# STM32L562 register map
File version: 1.1
Registers are 16-bit, read-write, reset 0x0 unless marked. A register's access mark holds for its fields unless they carry their own. Offsets are from the block's base; lines under a group give offsets from that group; [hi:lo] are bit positions; {n}, {i} and the like mark numbered series; 'fields as' and 'values as' point back to an identical list; <NAME> marks a mode.

## Memory map
0x4000D400 USB size 0x800 — Universal serial bus full-speed device interface

## Interrupts
73 USB_FS (USB) — USB FS global interrupt

## USB — Universal serial bus full-speed device interface
Base 0x4000D400
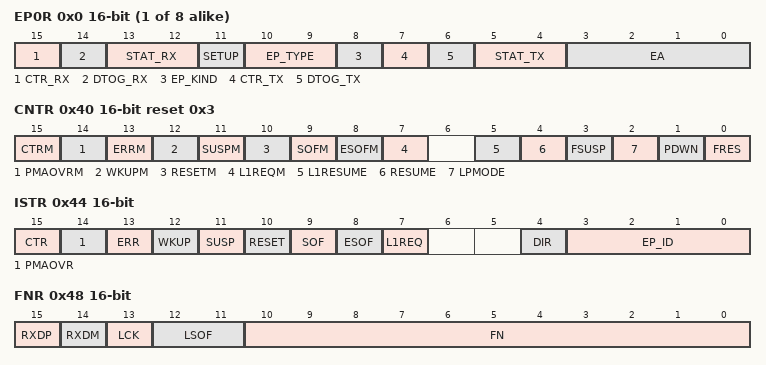
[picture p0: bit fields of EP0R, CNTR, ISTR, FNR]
{0x0+4i} EP{i}R (i=0..7) — endpoint {i} register
  [15] CTR_RX — Correct transfer for reception
  [14] DTOG_RX — Data Toggle, for reception transfers
  [13:12] STAT_RX — Status bits, for reception transfers
  [11] SETUP — Setup transaction completed
  [10:9] EP_TYPE — Endpoint type
  [8] EP_KIND — Endpoint kind
  [7] CTR_TX — Correct Transfer for transmission
  [6] DTOG_TX — Data Toggle, for transmission transfers
  [5:4] STAT_TX — Status bits, for transmission transfers
  [3:0] EA — Endpoint address
0x40 CNTR reset 0x3 — control register
  [15] CTRM — Correct transfer interrupt mask
  [14] PMAOVRM — Packet memory area over / underrun interrupt mask
  [13] ERRM — Error interrupt mask
  [12] WKUPM — Wakeup interrupt mask
  [11] SUSPM — Suspend mode interrupt mask
  [10] RESETM — USB reset interrupt mask
  [9] SOFM — Start of frame interrupt mask
  [8] ESOFM — Expected start of frame interrupt mask
  [7] L1REQM — LPM L1 state request interrupt mask
  [5] L1RESUME — LPM L1 Resume request
  [4] RESUME — Resume request
  [3] FSUSP — Force suspend
  [2] LPMODE — Low-power mode
  [1] PDWN — Power down
  [0] FRES — Force USB Reset
0x44 ISTR access per field — interrupt status register
  [15] CTR ro — Correct transfer
  [14] PMAOVR rw — Packet memory area over / underrun
  [13] ERR rw — Error
  [12] WKUP rw — Wakeup
  [11] SUSP rw — Suspend mode request
  [10] RESET rw — reset request
  [9] SOF rw — start of frame
  [8] ESOF rw — Expected start frame
  [7] L1REQ rw — LPM L1 state request
  [4] DIR ro — Direction of transaction
  [3:0] EP_ID ro — Endpoint Identifier
0x48 FNR ro — frame number register
  [15] RXDP — Receive data + line status
  [14] RXDM — Receive data - line status
  [13] LCK — Locked
  [12:11] LSOF — Lost SOF
  [10:0] FN — Frame number
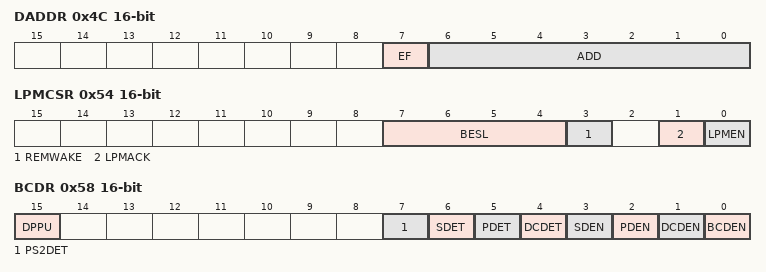
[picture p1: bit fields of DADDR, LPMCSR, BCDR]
0x4C DADDR — device address
  [7] EF — Enable function
  [6:0] ADD — Device address
0x50 BTABLE — Buffer table address
  [15:3] BTABLE — Buffer table
0x54 LPMCSR — LPM control and status register
  [7:4] BESL — BESL value
  [3] REMWAKE — RemoteWake value
  [1] LPMACK — LPM Token acknowledge enable
  [0] LPMEN — LPM support enable
0x58 BCDR — Battery charging detector
  [15] DPPU — DP pull-up control
  [7] PS2DET — DM pull-up detection status
  [6] SDET — Secondary detection (SD) status
  [5] PDET — Primary detection (PD) status
  [4] DCDET — Data contact detection (DCD) status
  [3] SDEN — Secondary detection (SD) mode enable
  [2] PDEN — Primary detection (PD) mode enable
  [1] DCDEN — Data contact detection (DCD) mode enable
  [0] BCDEN — Battery charging detector (BCD) enable
